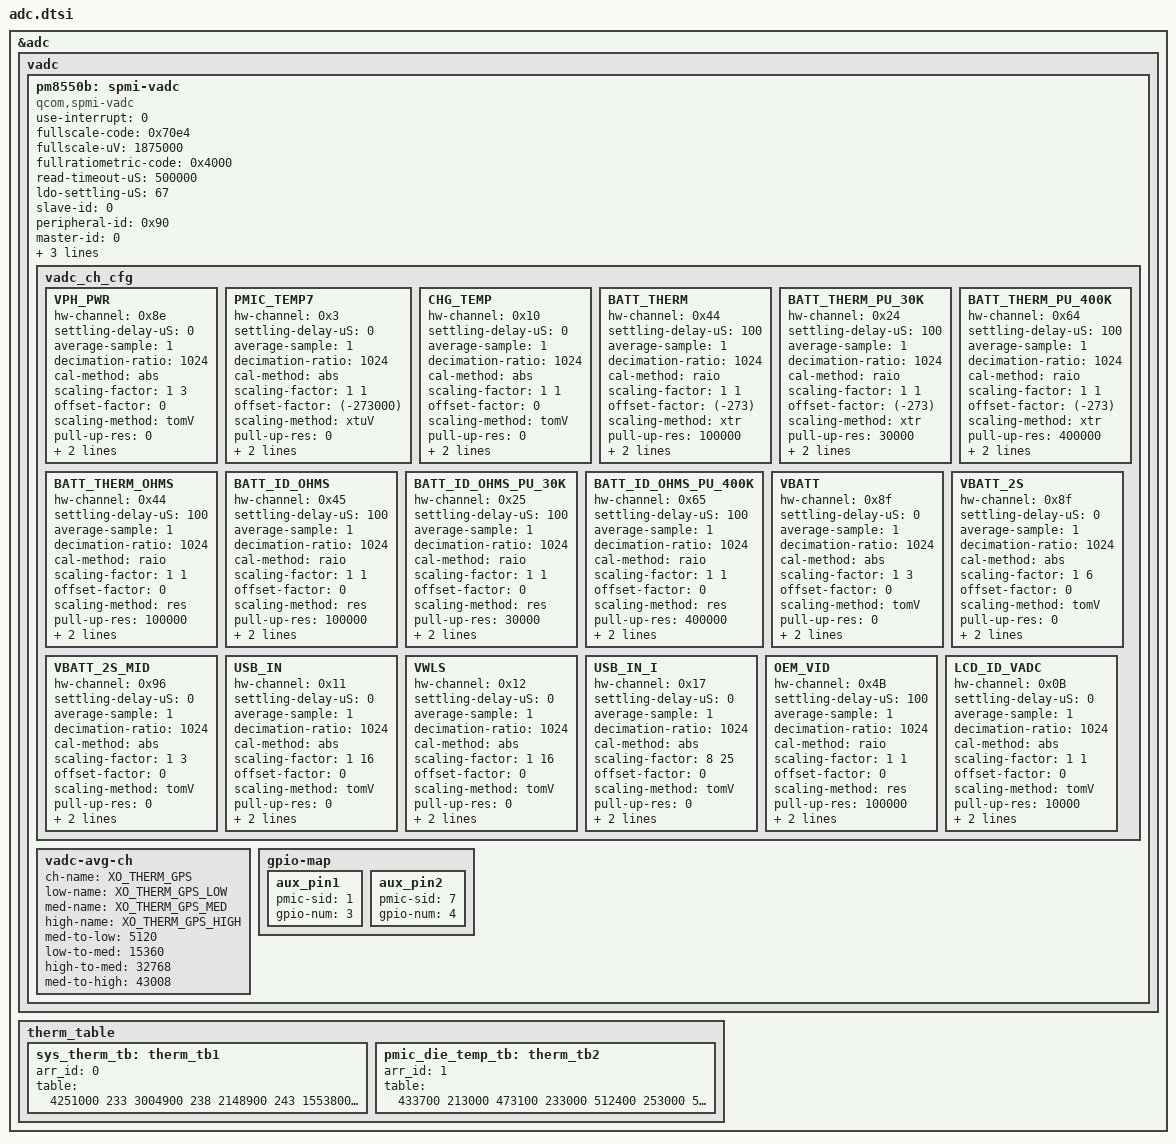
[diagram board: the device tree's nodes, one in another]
&adc {
	vadc: vadc {
   pm8550b: spmi-vadc {
      compatible = "qcom,spmi-vadc";
   
      use-interrupt = <0>;
      fullscale-code = <0x70e4>;             
      fullscale-uV = <1875000>;
      fullratiometric-code = <0x4000>;
      read-timeout-uS = <500000>;
      ldo-settling-uS = <67>;
      slave-id = <0>;            /* SID for Azura, main ADC interface */
      peripheral-id = <0x90>;    /* PID for ADC_APSS_SDAM instance used */
      master-id = <0>;
      pmic-device = <0>;
      bus-id = <0>;              /* SPMI bus id for Azura */
      therm-tbl = <&therm_table>;
   
      vadc_ch_cfg { 
         VPH_PWR {
            hw-channel = <0x8e>;
            settling-delay-uS = <0>;
            average-sample = <1>;
            decimation-ratio = <1024>;
            cal-method = "abs ";
            scaling-factor = <1 3>;    /* Scaling factor N / D */
            offset-factor = <0>;       /* Offset value after scaling */
            scaling-method = "tomV";   /* Value scale to mV */
            pull-up-res = <0>;
            adc-sid = <0x7>;
            int-table;
         };
         
         PMIC_TEMP7 {
            hw-channel = <0x3>;
            settling-delay-uS = <0>;
            average-sample = <1>;
            decimation-ratio = <1024>;
            cal-method = "abs ";
            scaling-factor = <1 1>;
            offset-factor = <(-273000)>;
            scaling-method = "xtuV";
            pull-up-res = <0>;
            adc-sid = <0x7>;
            int-table = &pmic_die_temp_tb;
         };
         
         CHG_TEMP {
            hw-channel = <0x10>;
            settling-delay-uS = <0>;
            average-sample = <1>;
            decimation-ratio = <1024>;
            cal-method = "abs ";
            scaling-factor = <1 1>;
            offset-factor = <0>;
            scaling-method = "tomV";
            pull-up-res = <0>;
            adc-sid = <0x7>;
            int-table;
         };
         
         BATT_THERM {
            hw-channel = <0x44>;
            settling-delay-uS = <100>;
            average-sample = <1>;
            decimation-ratio = <1024>;
            cal-method = "raio";
            scaling-factor = <1 1>;
            offset-factor = <(-273)>;
            scaling-method = "xtr ";
            pull-up-res = <100000>;
            adc-sid = <0x7>;
            int-table = &sys_therm_tb;
         };
         
         BATT_THERM_PU_30K {
            hw-channel = <0x24>;
            settling-delay-uS = <100>;
            average-sample = <1>;
            decimation-ratio = <1024>;
            cal-method = "raio";
            scaling-factor = <1 1>;
            offset-factor = <(-273)>;
            scaling-method = "xtr ";
            pull-up-res = <30000>;
            adc-sid = <0x7>;
            int-table = &sys_therm_tb;
         };
         
         BATT_THERM_PU_400K {
            hw-channel = <0x64>;
            settling-delay-uS = <100>;
            average-sample = <1>;
            decimation-ratio = <1024>;
            cal-method = "raio";
            scaling-factor = <1 1>;
            offset-factor = <(-273)>;
            scaling-method = "xtr ";
            pull-up-res = <400000>;
            adc-sid = <0x7>;
            int-table = &sys_therm_tb;
         };

         BATT_THERM_OHMS {
            hw-channel = <0x44>;
            settling-delay-uS = <100>;
            average-sample = <1>;
            decimation-ratio = <1024>;
            cal-method = "raio";
            scaling-factor = <1 1>;
            offset-factor = <0>;
            scaling-method = "res ";
            pull-up-res = <100000>;
            adc-sid = <0x7>;
            int-table;
         };
 
         BATT_ID_OHMS {
            hw-channel = <0x45>;
            settling-delay-uS = <100>;
            average-sample = <1>;
            decimation-ratio = <1024>;
            cal-method = "raio";
            scaling-factor = <1 1>;
            offset-factor = <0>;
            scaling-method = "res ";
            pull-up-res = <100000>;
            adc-sid = <0x7>;
            int-table;
         };

         BATT_ID_OHMS_PU_30K {
            hw-channel = <0x25>;
            settling-delay-uS = <100>;
            average-sample = <1>;
            decimation-ratio = <1024>;
            cal-method = "raio";
            scaling-factor = <1 1>;
            offset-factor = <0>;
            scaling-method = "res ";
            pull-up-res = <30000>;
            adc-sid = <0x7>;
            int-table;
         };
         
         BATT_ID_OHMS_PU_400K {
            hw-channel = <0x65>;
            settling-delay-uS = <100>;
            average-sample = <1>;
            decimation-ratio = <1024>;
            cal-method = "raio";
            scaling-factor = <1 1>;
            offset-factor = <0>;
            scaling-method = "res ";
            pull-up-res = <400000>;
            adc-sid = <0x7>;
            int-table;
         };
         
         VBATT {
            hw-channel = <0x8f>;
            settling-delay-uS = <0>;
            average-sample = <1>;
            decimation-ratio = <1024>;
            cal-method = "abs ";
            scaling-factor = <1 3>;
            offset-factor = <0>;
            scaling-method = "tomV";
            pull-up-res = <0>;
            adc-sid = <0x7>;
            int-table;
         };
         
         VBATT_2S {
            hw-channel = <0x8f>;
            settling-delay-uS = <0>;
            average-sample = <1>;
            decimation-ratio = <1024>;
            cal-method = "abs ";
            scaling-factor = <1 6>;
            offset-factor = <0>;
            scaling-method = "tomV";
            pull-up-res = <0>;
            adc-sid = <0x7>;
            int-table;
         };
         
         VBATT_2S_MID {
            hw-channel = <0x96>;
            settling-delay-uS = <0>;
            average-sample = <1>;
            decimation-ratio = <1024>;
            cal-method = "abs ";
            scaling-factor = <1 3>;
            offset-factor = <0>;
            scaling-method = "tomV";
            pull-up-res = <0>;
            adc-sid = <0x7>;
            int-table;
         };
         
         USB_IN {
            hw-channel = <0x11>;
            settling-delay-uS = <0>;
            average-sample = <1>;
            decimation-ratio = <1024>;
            cal-method = "abs ";
            scaling-factor = <1 16>;
            offset-factor = <0>;
            scaling-method = "tomV";
            pull-up-res = <0>;
            adc-sid = <0x7>;
            int-table;
         };

         VWLS {
            hw-channel = <0x12>;
            settling-delay-uS = <0>;
            average-sample = <1>;
            decimation-ratio = <1024>;
            cal-method = "abs ";
            scaling-factor = <1 16>;
            offset-factor = <0>;
            scaling-method = "tomV";
            pull-up-res = <0>;
            adc-sid = <0x7>;
            int-table;
         };
         
         USB_IN_I {
            hw-channel = <0x17>;
            settling-delay-uS = <0>;
            average-sample = <1>;
            decimation-ratio = <1024>;
            cal-method = "abs ";
            scaling-factor = <8 25>;
            offset-factor = <0>;
            scaling-method = "tomV";
            pull-up-res = <0>;
            adc-sid = <0x7>;
            int-table;
         };
         
         /* Channel to be used by OEMInfo driver; OEM's can map the ADC HW
          * channel per their reference design. If SID1-GPIO04 (AMUX2_GPIO) is
          * used the vadc-ch config & gpio-map nodes are updated, else please
          * update the vadc-ch & gpio-map accordingly per the board design.*/
         OEM_VID {
            hw-channel = <0x4B>;
            settling-delay-uS = <100>;
            average-sample = <1>;
            decimation-ratio = <1024>;
            cal-method = "raio";
            scaling-factor = <1 1>;
            offset-factor = <0>;
            scaling-method = "res ";
            pull-up-res = <100000>;
            adc-sid = <0x1>;
            int-table;
         };

         /* Added by SONY Start */
         LCD_ID_VADC {
            hw-channel = <0x0B>;
            settling-delay-uS = <0>;
            average-sample = <1>;
            decimation-ratio = <1024>;
            cal-method = "abs ";
            scaling-factor = <1 1>;
            offset-factor = <0>;
            scaling-method = "tomV";
            pull-up-res = <10000>;
            adc-sid = <0x7>;
            int-table;
         };
         /* Added by SONY End */
      };
   
      vadc-avg-ch {
         ch-name = "XO_THERM_GPS";
         low-name = "XO_THERM_GPS_LOW";
         med-name = "XO_THERM_GPS_MED";
         high-name = "XO_THERM_GPS_HIGH";
         med-to-low = <5120>;
         low-to-med = <15360>;
         high-to-med = <32768>;
         med-to-high = <43008>;
      };
   
      gpio-map { 
         /* For GPIO that need to be used for ADC input, 
            Set the PMIC SID + GPIO number here. */
         aux_pin1 {
            pmic-sid = <1>;
            gpio-num = <3>;
         };
         /* Added by SONY Start */
         aux_pin2 {
            pmic-sid = <7>;
            gpio-num = <4>;
         };
         /* Added by SONY End */
      };
   	};
	};
  therm_table: therm_table { };
};

&therm_table {
   sys_therm_tb: therm_tb1 {
      /* Resistance to Degree K for NTCG104EF104FB */
      arr_id = <0>;
      table = <
          4251000 233
          3004900 238
          2148900 243
          1553800 248
          1135300 253
           837800 258
           624100 263
           469100 268
           355600 273
           271800 278
           209400 283
           162500 288
           127000 293
           100000 298
            79200 303
            63200 308
            50700 313
            40900 318
            33200 323
            27100 328
            22200 333
            18300 338
            15200 343
            12600 348
            10600 353
             8890 358
             7500 363
             6360 368
             5410 373
             4620 378
             3970 383
             3420 388
             2950 393
             2560 398>;
   };

   pmic_die_temp_tb: therm_tb2 {
      /* Resistance to Degree mK */
      arr_id = <1>;
      table = <
        433700 213000
        473100 233000
        512400 253000
        551500 273000
        590500 293000
        629300 313000
        667900 333000
        706400 353000
        744600 373000
        782500 393000
        820100 413000>;
   };
};

